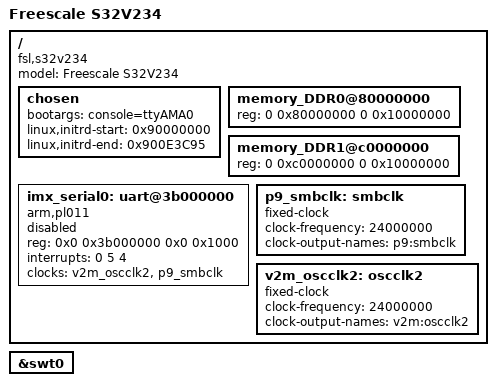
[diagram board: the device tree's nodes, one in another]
/*
 * Copyright 2015 Freescale Semiconductor, Inc.
 *
 * This program is free software; you can redistribute it and/or modify
 * it under the terms of the GNU General Public License as published by
 * the Free Software Foundation; either version 2 of the License, or
 * (at your option) any later version.
 */

/dts-v1/;
#include "s32v234.dtsi"
/ {
	model = "Freescale S32V234";
	compatible = "fsl,s32v234", "arm,vexpress,v2p-aarch64", "arm,vexpress";

	chosen {
		bootargs = "console=ttyAMA0";
		//bootargs = "root=/dev/ram rdinit=/bin/bash rw console=ttyAMA0 earlycon=pl011,0x40053000";
		linux,initrd-start = <0x90000000>;
		linux,initrd-end   = <0x900E3C95>;
	};

	memory_DDR0@80000000 {
		device_type = "memory";
		reg = <0 0x80000000 0 0x10000000>;
	};

	memory_DDR1@c0000000 {
		device_type = "memory";
		reg = <0 0xc0000000 0 0x10000000>;
	};

	imx_serial0: uart@3b000000 {
		compatible = "arm,pl011", "arm,primecell";
		reg = <0x0 0x3b000000 0x0 0x1000>;
		interrupts = <0 5 4>;
		clocks = <&v2m_oscclk2>, <&p9_smbclk>;
		clock-names = "uartclk", "apb_pclk";
		status = "okey";
	 };

	p9_smbclk: smbclk {
		/* Static memory controller clock */
		compatible = "fixed-clock";
		#clock-cells = <0>;
		clock-frequency = <24000000>;
		clock-output-names = "p9:smbclk";
	};

	v2m_oscclk2: oscclk2 {
		/* IO FPGA peripheral clock */
		compatible = "fixed-clock";
		#clock-cells = <0>;
		clock-frequency = <24000000>;
		clock-output-names = "v2m:oscclk2";
	};

};

&swt0 {
	status = "okay";
};

